# DSP_SYSTEM register map
Vendor: Texas Instruments
Peripheral module from a debugger description file (folder DRA72x).
Registers are 32-bit, read-write, reset 0x0 unless marked. A register's access mark holds for its fields unless they carry their own. Offsets are as the file gives them; lines under a group give offsets from that group; [hi:lo] are bit positions; {n}, {i} and the like mark numbered series; 'fields as' and 'values as' point back to an identical list; <NAME> marks a mode.

## DSP_SYSTEM
0x00 DSP_SYS_REVISION ro reset not defined
  [31:0] REVISION — IP Revision
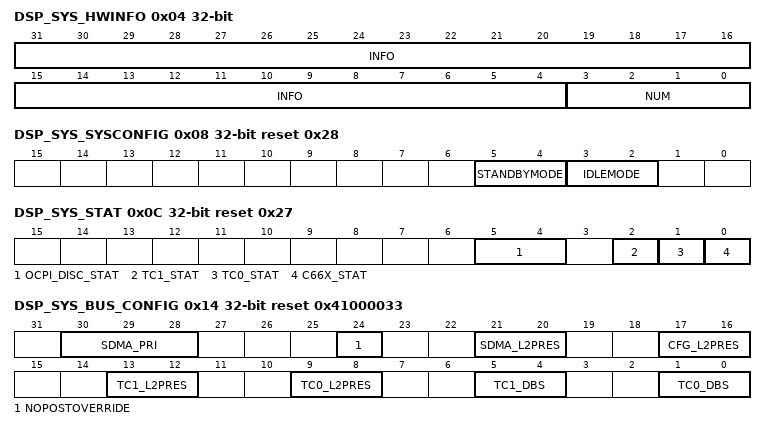
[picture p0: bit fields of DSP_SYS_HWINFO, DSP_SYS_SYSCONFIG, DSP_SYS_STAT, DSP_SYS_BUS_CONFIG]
0x04 DSP_SYS_HWINFO ro
  [31:4] INFO — 0x0: No configurable options in subsystem.
  [3:0] NUM — Instance Number Set by subsystem input. In a multi-DSP system, provides a unique/incrementing values for each DSP.
0x08 DSP_SYS_SYSCONFIG access per field reset 0x28
  [5:4] STANDBYMODE rw — 0x0: FORCE_STANDBY This mode is a backup mode intended to be used only if the smart-idle mode is bugged. When in this mode, the SAF asserts with minimal hardware condition the 'STANDBY' status. It is the responsibility of the software to ensure that the SAF is in a correct quiet state before programming this mode. Additionally when in this mode, the SAF is not allowed to generate wakeup request.
    1=NO_STANDBY_SAF_"STANDBY"_1 (NO_STANDBY This mode is a backup mode intended to be used only if the smart-idle mode is bugged. When in this mode, the SAF in C66xOSS asserts the 'STANDBY' status.); 2=SMART_STANDBY_SAF_2 (SMART_STANDBY default. C66xOSS generates the standby status based upon all hardware internal status, namely after having performed all hardware operations necessary to be in a correct quiet state. Additionally when in this mode, the SAF is not allowed to generate wakeup request.); 3=SMART_STANDBY_WKUP_SAF_3 (SMART_STANDBY_WKUP Same as Smart-Standby. (C66xOSS generates the standby status based upon all hardware internal status, namely after having performed all hardware operations necessary to be in a correct quiet state ). . Additionally when in this mode, the SAF is allowed to generate wakeup request)
  [3:2] IDLEMODE rw — 0x0: FORCE_IDLE This mode is a backup mode intended to be used only if the smart-idle mode is bugged. When in this mode, the IAF acknowledges a request to go idle from the power manager with minimal hardware condition. It is the responsibility of the software to ensure that the IAF are in a correct quiet state before requesting a force-idle transition. Additionally when in this mode, the IAF is not allowed to generate any wakeup request.
    1=NO_IDLE_IAF_1 (NO_IDLE When in this mode, the IAF disregards any request to go idle from the power manager.); 2=SMART_IDLE_IAF_IAF_2 (SMART_IDLE default. When in this mode, the IAF acknowledges a request to go idle from the power manager after having performed all hardware operations necessary to be in a correct quiet state. Additionally when in this mode, the IAF is not allowed to generate any wakeup request); 3=SMARTIDLEWKUP_IAF_IAF_IAF_3 (SMARTIDLEWKUP When in this mode, the IAF acknowledges a request to go idle from the power manager after having performed all hardware operations necessary for the IAF to be in a correct quiet state. Additionally when in this mode, the IAF is allowed to generate wakeup request.)
0x0C DSP_SYS_STAT ro reset 0x27 — This register is intended to provide indication to software (including a remote host) as to whether the DSP is able to enter a low power mode.
  [5:4] OCPI_DISC_STAT — L3_MAIN (OCP) Initiator(s) Disconnect Status
    0=OCP_inititiator_ports_are_disconnected; 1=OCP_1 (OCP initiator ports are attempting to disconnect.); 2=OCP_2 (OCP initiator ports are active, no request to disconnect is pending.)
  [2] TC1_STAT — EDMA TC1 Status
    0=IDLE; 1=ACTIVE (ACTIVE - Active, based on inverse of tptc1_mstandby)
  [1] TC0_STAT — EDMA TC0 Status
    0=IDLE; 1=ACTIVE (ACTIVE - Active, based on inverse of tptc0_mstandby)
  [0] C66X_STAT — C66x Status
    0=IDLE (IDLE C66x core is idle); 1=ACTIVE (ACTIVE C66x core is active.)
0x10 DSP_SYS_DISC_CONFIG access per field — This register is used to manually disconnect the OCP busses.
  [0] OCPI_DISC rw — OCP Initiator (on L3_MAIN) Disconnect request
    0=OCPI_DISC_0_r (Disconnect not in progress, or has completed.); 0=No_effect; 1=Disconnect_request_is_in_progress; 1=OCP_1 (Request for OCP Initiator to disconnect and mask write byte enable signals.)
0x14 DSP_SYS_BUS_CONFIG access per field reset 0x41000033 — This register controls the burst and priority settings for the internal initiators.
  [30:28] SDMA_PRI rw — Sets the CBA/VBusM Priority for the DSP C66x CorePac SDMA port. Can typically be left at default value. 0x0 is highest, ..., 0x7 is lowest priority.
  [24] NOPOSTOVERRIDE rw — OCP Posted Write vs Non-Posted Write override
    0=MIX (MIX Posted writes are used for cacheable write transactions. Non-posted writes are used for non-cacheable write transactions.); 1=NOPOST (NOPOST Non-posted writes are used exclusively.)
  [21:20] SDMA_L2PRES rw — OCP Target port L2 Interconnect Pressure. Driven on ocp mflag to control arbitration within the L2 interconnect.
    0=LOW_-_Lowest_pressure; 1=MED_-_Medium_pressure; 3=HIGH_-_High_pressure
  [17:16] CFG_L2PRES rw — DSP CFG L2 Interconnect Pressure. Driven on ocp mflag to control arbitration within the L2 interconnect
    values as SDMA_L2PRES
  [13:12] TC1_L2PRES rw — TC1 L2 Interconnect Pressure. Driven on ocp mflag to control arbitration within the L2 interconnect
    values as SDMA_L2PRES
  [9:8] TC0_L2PRES rw — TC0 L2 Interconnect Pressure. Driven on ocp mflag to control arbitration within the L2 interconnect.
    values as SDMA_L2PRES
  [5:4] TC1_DBS rw — TC1 Default Burst size.
    0=BYTE_16_-_"16-Byte"_bursts; 1=BYTE_32_-_"32-Byte"_bursts; 2=BYTE_64_-_"64-Byte"_bursts; 3=BYTE_128_-_"128-Byte"_bursts
  [1:0] TC0_DBS rw — TC0 Default Burst size
    values as TC1_DBS
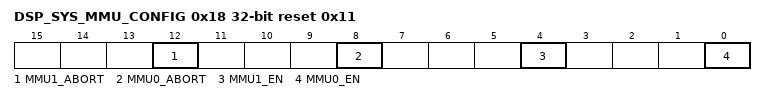
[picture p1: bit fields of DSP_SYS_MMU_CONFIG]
0x18 DSP_SYS_MMU_CONFIG access per field reset 0x11 — This register is used to enable the subsystem MMUs.
  [12] MMU1_ABORT rw — MU1 Abort
    0=NOABORT (NOABORT = Abort not requested.); 1=ABORT (ABORT = MMU abort requested. Can be used in case of page translation failure or lockup.)
  [8] MMU0_ABORT rw — MU0 Abort
    values as MMU1_ABORT
  [4] MMU1_EN rw — MU1 Enable
    0=DISABLED (DISABLED = MMU is disabled and the MMU IP is bypassed.); 1=ENABLED (ENABLED = MMU is enabled. (The MMU mmrs (including Enable bit) need to be set in addition to this bit.))
  [0] MMU0_EN rw — MU1 Enable
    values as MMU1_EN
0x20 DSP_SYS_IRQWAKEEN0 — The register provides a global interrupt wakeup enable bit vector that defines which input interrupts are used to cause a wake from powerdown state (via the slave idle protocol). IRQWAKEEN0 is for interrupt inputs 63 thru 32, and IRQWAKEEN1 is for interrupt inputs 95 thru 64. Internal interrupts cannot cause a wake condition since in this state there is no guaranteed clock and all sub-modules should be in idle state. Software can write 1 to set and 0 to clear the corresponding bit (i.e., enable the corresponding interrupt for wakeup). Reads of this register return the actual state of the enable register.
  [31:0] ENABLE — Wakeup Enable bit vector for interrupt #n+32
    0=DISABLE (DISABLE = Interrupt #n+32 disabled for wakeup); 1=ENABLE (ENABLE = Interrupt #n+32 enabled for wakeup)
0x24 DSP_SYS_IRQWAKEEN1 — The register provides a global interrupt wakeup enable bit vector that defines which input interrupts are used to cause a wake from powerdown state (via the slave idle protocol). IRQWAKEEN0 is for interrupt inputs 63 thru 32, and IRQWAKEEN1 is for interrupt inputs 95 thru 64. Internal interrupts cannot cause a wake condition since in this state there is no guaranteed clock and all sub-modules should be in idle state. Software can write 1 to set and 0 to clear the corresponding bit (i.e., enable the corresponding interrupt for wakeup). Reads of this register return the actual state of the enable register.
  [31:0] ENABLE — Wakeup Enable bit vector for interrupt #n+64
    0=DISABLE (DISABLE = Interrupt #n+64 disabled for wakeup); 1=ENABLE (ENABLE = Interrupt #n+64 enabled for wakeup)
0x30 DSP_SYS_DMAWAKEEN0 — The register provides a global dma event wakeup enable bit vector that defines which input dma events are used to cause a wake from powerdown state (via the slave idle protocol). DMAWAKEEN0 is for dma event inputs 31 thru 0, and DMAWAKEEN1 is for dma event inputs 63 thru 32. Software can write 1 to set and 0 to clear the corresponding bit (i.e., enable the corresponding dma event for wakeup). Reads of this register return the actual state of the enable register.
  [31:0] ENABLE — Wakeup Enable for event #n
    0=DISABLE (DISABLE = Interrupt #n disabled for wakeup); 1=ENABLE (ENABLE = Interrupt #n enabled for wakeup)
0x34 DSP_SYS_DMAWAKEEN1 — The register provides a global dma event wakeup enable bit vector that defines which input dma events are used to cause a wake from powerdown state (via the slave idle protocol). DMAWAKEEN0 is for dma event inputs 31 thru 0, and DMAWAKEEN1 is for dma event inputs 63 thru 32. Software can write 1 to set and 0 to clear the corresponding bit (i.e., enable the corresponding dma event for wakeup). Reads of this register return the actual state of the enable register.
  [31:0] ENABLE — Wakeup Enable for event #n+32
    values as DSP_SYS_IRQWAKEEN0.ENABLE
0x40 DSP_SYS_EVTOUT_SET — These registers can be used to drive event outputs from the DSP subsystem to a desired state.
  [31:0] EVENT — Output Event for event #n
    1=Drive_output_event_#n_high/1; 0=Event_#n_is_low/0; 1=Event_#n_is_high/1; 0=No_action
0x44 DSP_SYS_EVTOUT_CLR — These registers can be used to drive event outputs from the DSP subsystem to a desired state.
  [31:0] EVENT — Output Event for event #n
    0=Event_#n_is_low/0; 1=Drive_output_event_#n_low/0; 1=Event_#n_is_high/1; 0=No_action
0x50 DSP_SYS_ERRINT_IRQSTATUS_RAW access per field — This register provides a per-event raw interrupt status vector
  [18:0] EVENT rw — Settable raw status for event #n
    0=No_event_pending; 0=No_action; 1=Event_pending; 1=Set_event_(for_debug)
0x54 DSP_SYS_ERRINT_IRQSTATUS access per field — This register provides a per-event enabled interrupt status vector.
  [18:0] EVENT rw — Clearable, enabled status for event #n
    0=No_enabled_event_pending; 0=No_action; 1=Enabled_Event_pending; 1=Clear_raw_event
0x58 DSP_SYS_ERRINT_IRQENABLE_SET access per field — This register provides a per-event interrupt enable bit vector.
  [18:0] ENABLE rw — Enable for event #n
    0=Interrupt_disabled; 0=No_action; 1=Interrupt_enabled; 1=Enable_interrupt
0x5C DSP_SYS_ERRINT_IRQENABLE_CLR access per field — This register provides a per-event interrupt enable bit vector.
  [18:0] ENABLE rw — Enable for event #n
    0=Interrupt_disabled; 0=No_action; 1=Interrupt_enabled; 1=ENABLE_1_w (Disable interrupt (i.e., clear ENABLEn bit))
0x60 DSP_SYS_EDMAWAKE0_IRQSTATUS_RAW — This register provides a per-event raw interrupt status vector
  [31:0] EVENT — Settable raw status for event #n
    0=No_event_pending; 1=Set_event_(for_debug); 1=Event_pending; 0=No_action
0x64 DSP_SYS_EDMAWAKE0_IRQSTATUS — This register provides a per-event enabled interrupt status vector.
  [31:0] EVENT — Clearable, enabled status for event #n
    0=No_enabled_event_pending; 1=Clear_raw_event; 1=Enabled_Event_pending; 0=No_action
0x68 DSP_SYS_EDMAWAKE0_IRQENABLE_SET — This register provides a per-event interrupt enable bit vector.
  [31:0] ENABLE — Enable for event #n
    0=Interrupt_disabled; 1=Enable_interrupt; 1=Interrupt_enabled; 0=No_action
0x6C DSP_SYS_EDMAWAKE0_IRQENABLE_CLR — This register provides a per-event interrupt enable bit vector.
  [31:0] ENABLE — Enable for event #n
    0=Interrupt_disabled; 1=ENABLE_1_w (Disable interrupt (i.e., clear ENABLEn bit)); 1=Interrupt_enabled; 0=No_action
0x70 DSP_SYS_EDMAWAKE1_IRQSTATUS_RAW — This register provides a per-event raw interrupt status vector
  [31:0] EVENT — Settable raw status for event #n+32
    values as DSP_SYS_EDMAWAKE0_IRQSTATUS_RAW.EVENT
0x74 DSP_SYS_EDMAWAKE1_IRQSTATUS — This register provides a per-event enabled interrupt status vector.
  [31:0] EVENT — Clearable, enabled status for event #n+32
    values as DSP_SYS_EDMAWAKE0_IRQSTATUS.EVENT
0x78 DSP_SYS_EDMAWAKE1_IRQENABLE_SET — This register provides a per-event interrupt enable bit vector.
  [31:0] ENABLE — Enable for event #n+32
    values as DSP_SYS_EDMAWAKE0_IRQENABLE_SET.ENABLE
0x7C DSP_SYS_EDMAWAKE1_IRQENABLE_CLR — This register provides a per-event interrupt enable bit vector.
  [31:0] ENABLE — Enable for event #n+32
    values as DSP_SYS_EDMAWAKE0_IRQENABLE_CLR.ENABLE
0xF8 DSP_SYS_HW_DBGOUT_SEL access per field — This register is used to select which group of internal signals are mapped to the hw_dbgout output bus.
  [3:0] GROUP rw — Debug Group output control mux selectN: GN = select output group N .
    0=Disabled,_debug_outputs_driven_to_0x0; 1=G1_=_select_output_group_1; 2=G2_=_select_output_group_2
0xFC DSP_SYS_HW_DBGOUT_VAL ro — This register is used to read the value of the currently selected debug output group.
  [31:0] VALUE — Read returns state of hw_dbgout bus
